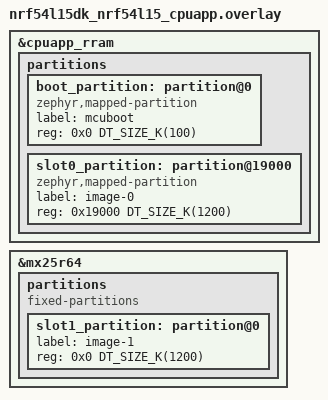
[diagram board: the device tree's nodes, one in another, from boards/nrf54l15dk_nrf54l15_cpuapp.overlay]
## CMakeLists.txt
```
#
# Copyright (c) 2024 Nordic Semiconductor
#
# SPDX-License-Identifier: LicenseRef-Nordic-5-Clause
#

cmake_minimum_required(VERSION 3.20.0)
find_package(Zephyr REQUIRED HINTS $ENV{ZEPHYR_BASE})
project(l9)

target_sources(app PRIVATE src/main.c)
```

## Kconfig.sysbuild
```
#
# Copyright (c) 2024 Nordic Semiconductor
#
# SPDX-License-Identifier: LicenseRef-Nordic-5-Clause
#

source "${ZEPHYR_BASE}/share/sysbuild/Kconfig"

config PARTITION_MANAGER
	default n
```

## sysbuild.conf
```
# MCUboot
SB_CONFIG_BOOTLOADER_MCUBOOT=y
SB_CONFIG_PARTITION_MANAGER=n

# MCUboot should use external flash
SB_CONFIG_PM_EXTERNAL_FLASH_MCUBOOT_SECONDARY=y
```

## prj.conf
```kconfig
CONFIG_GPIO=y

# Enable mcumgr DFU in application
CONFIG_MCUMGR=y
CONFIG_UART_MCUMGR=y
CONFIG_MCUMGR_TRANSPORT_UART=y

# Enable MCUMGR management for both OS and Images
CONFIG_MCUMGR_GRP_OS=y
CONFIG_MCUMGR_GRP_IMG=y

# Configure MCUMGR transport to UART
CONFIG_MCUMGR_TRANSPORT_UART=y

# Dependencies
# Configure dependencies for CONFIG_MCUMGR  
CONFIG_NET_BUF=y
CONFIG_ZCBOR=y
CONFIG_CRC=y

# Configure dependencies for CONFIG_MCUMGR_GRP_IMG  
CONFIG_FLASH=y
CONFIG_IMG_MANAGER=y

# Configure dependencies for CONFIG_IMG_MANAGER  
CONFIG_STREAM_FLASH=y
CONFIG_FLASH_MAP=y

# Configure dependencies for CONFIG_MCUMGR_TRANSPORT_UART 
CONFIG_BASE64=y
```

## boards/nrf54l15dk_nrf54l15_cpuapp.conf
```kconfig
# Enable QSPI driver for Application
CONFIG_NORDIC_QSPI_NOR=y
```

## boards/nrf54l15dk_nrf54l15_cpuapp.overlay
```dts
/delete-node/ &boot_partition;
/delete-node/ &slot0_partition;
/delete-node/ &slot1_partition;

&cpuapp_rram {
    partitions {
        boot_partition: partition@0 {
            compatible = "zephyr,mapped-partition";
            label = "mcuboot";
            reg = <0x0 DT_SIZE_K(100)>;
        };

        slot0_partition: partition@19000 {
            compatible = "zephyr,mapped-partition";
            label = "image-0";
            reg = <0x19000 DT_SIZE_K(1200)>;
        };
    };
};

/* Add external flash to application */
&mx25r64 {
    status = "okay";
    partitions {
        compatible = "fixed-partitions";
        #address-cells = <1>;
        #size-cells = <1>;

        slot1_partition: partition@0 {
            label = "image-1";
            reg = <0x0 DT_SIZE_K(1200)>;
        };
    };
};
```

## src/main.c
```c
/*
 * Copyright (c) 2016 Intel Corporation
 *
 * SPDX-License-Identifier: Apache-2.0
 */

#include <zephyr/kernel.h>
#include <zephyr/drivers/gpio.h>
#include <zephyr/logging/log.h>

LOG_MODULE_REGISTER(Lesson9_Exercise1, LOG_LEVEL_INF);

/* 1000 msec = 1 sec */

/* Change LED timing to create a new image for DFU*/
#define SLEEP_TIME_MS   100

/* The devicetree node identifier for the "led0" alias. */
#define LED0_NODE DT_ALIAS(led0)

/*
 * A build error on this line means your board is unsupported.
 * See the sample documentation for information on how to fix this.
 */
static const struct gpio_dt_spec led = GPIO_DT_SPEC_GET(LED0_NODE, gpios);

int main(void)
{
	int ret;

	if (!device_is_ready(led.port)) {
		return -1;
	}

	ret = gpio_pin_configure_dt(&led, GPIO_OUTPUT_ACTIVE);
	if (ret < 0) {
		return -1;
	}

	while (1) {
		ret = gpio_pin_toggle_dt(&led);
		if (ret < 0) {
			return -1;
		}
		k_msleep(SLEEP_TIME_MS);
	}
}
```
